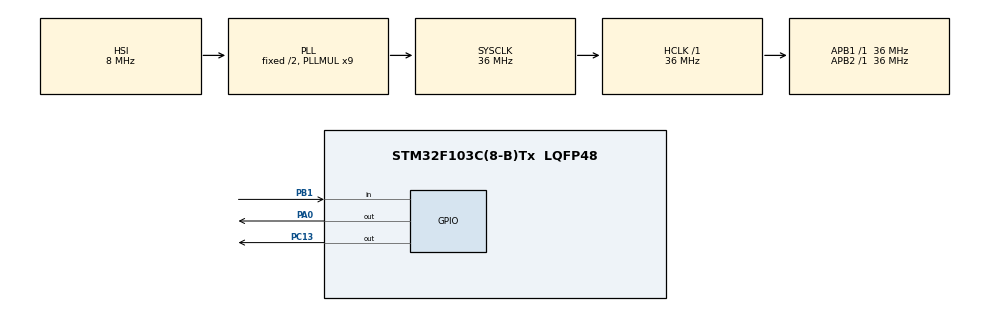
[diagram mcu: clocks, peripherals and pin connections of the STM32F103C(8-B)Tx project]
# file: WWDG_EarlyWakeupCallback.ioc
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Mcu.Family=STM32F1
Mcu.Name=STM32F103C(8-B)Tx
Mcu.Package=LQFP48
NVIC.PriorityGroup=NVIC_PRIORITYGROUP_4
NVIC.WWDG_IRQn=true\:0\:0\:false\:false\:true\:true\:true
PA0-WKUP.Signal=GPIO_Output
PA13.Mode=Serial_Wire
PA13.Signal=SYS_JTMS-SWDIO
PA14.Mode=Serial_Wire
PA14.Signal=SYS_JTCK-SWCLK
PB1.GPIO_PuPd=GPIO_PULLUP
PB1.Signal=GPIO_Input
PC13-TAMPER-RTC.Signal=GPIO_Output
ProjectManager.HeapSize=0x200
ProjectManager.StackSize=0x400
ProjectManager.TargetToolchain=MDK-ARM V5
RCC.AHBFreq_Value=36000000
RCC.APB1Freq_Value=36000000
RCC.APB1TimFreq_Value=36000000
RCC.APB2Freq_Value=36000000
RCC.APB2TimFreq_Value=36000000
RCC.HCLKFreq_Value=36000000
RCC.PLLMUL=RCC_PLL_MUL9
RCC.SYSCLKFreq_VALUE=36000000
RCC.SYSCLKSource=RCC_SYSCLKSOURCE_PLLCLK
RCC.USBFreq_Value=36000000
VP_WWDG_VS_WWDG.Mode=WWDG_Activate
WWDG.Counter=127
WWDG.EWIMode=WWDG_EWI_ENABLE
WWDG.Prescaler=WWDG_PRESCALER_8
WWDG.Window=80
board=custom

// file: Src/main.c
/* USER CODE BEGIN Header */
/**
  ******************************************************************************
  * @file           : main.c
  * @brief          : Main program body
  ******************************************************************************
  * @attention
  *
  * <h2><center>&copy; Copyright (c) 2019 STMicroelectronics.
  * All rights reserved.</center></h2>
  *
  * This software component is licensed by ST under BSD 3-Clause license,
  * the "License"; You may not use this file except in compliance with the
  * License. You may obtain a copy of the License at:
  *                        opensource.org/licenses/BSD-3-Clause
  *
  ******************************************************************************
  */
	/* --COPYRIGHT--,
	 * Copyright (c) 2019, TAPIT Co., Ltd.
	 * https://tapit.vn
	 * ***************************** WWDG_EarlyWakeupCallback *****************************
	 *  Description: The program consists of 2 initial status LEDs that are off. An LED will
			reverse the state to check the operation of the MCU. The remaining LED will be
			turned on when entering the EWC function, off when MCU is reset.
	 *  Version:    1.0
	 *  Author:     Hang Tran
	 *  Release:    May 27, 2019
	 *  Built with CubeMX Version 5.2.0 and Keil C Version 5.26.2
	 **************************************************************************************
 */
/* USER CODE END Header */

#include "main.h"

WWDG_HandleTypeDef hwwdg;

/* USER CODE BEGIN PV */
unsigned char cnt = 0; // Temporary variable for counter value
unsigned char wdt = 0; // Temporary variable for window value

/* USER CODE END PV */

void SystemClock_Config(void);
static void MX_GPIO_Init(void);
static void MX_WWDG_Init(void);
/* USER CODE BEGIN PFP */
void HAL_WWDG_EarlyWakeupCallback(WWDG_HandleTypeDef *hwwdg)
{
	wdt = 0;	// Reset variable for counter value
	cnt = 0;  // Reset variable for window value
	wdt = (WWDG->CFR & 0x7F);      // Read window value
  cnt = (WWDG->CR & 0x7F);       // Read counter value
	if(cnt < wdt)
	{
		WWDG->CR |= 0x7F; 											// Reload the counter to prevent reset MCU
		WWDG->SR = 0x00;												// Clear interrupt flag
		HAL_GPIO_WritePin(GPIOA, GPIO_PIN_0, GPIO_PIN_SET); 			// Watchdog led on
	}
}

/* USER CODE END PFP */

int main(void)
{

  /* MCU Configuration--------------------------------------------------------*/

  /* Reset of all peripherals, Initializes the Flash interface and the Systick. */
  HAL_Init();

  /* Configure the system clock */
  SystemClock_Config();

  /* Initialize all configured peripherals */
  MX_GPIO_Init();
  MX_WWDG_Init();
  /* USER CODE BEGIN 2 */
	HAL_GPIO_WritePin(GPIOA, GPIO_PIN_0, GPIO_PIN_RESET);			// Watchdog LED - off
	HAL_GPIO_WritePin(GPIOC, GPIO_PIN_13, GPIO_PIN_SET); 		// Main LED - off
	HAL_Delay(2000);

  /* USER CODE END 2 */

  /* Infinite loop */
  while (1)
  {

    /* USER CODE BEGIN 3 */
		HAL_GPIO_TogglePin(GPIOC, GPIO_PIN_13); // To show that normal operation is OK
		HAL_Delay(300); // Toggle led every 300ms
		if(HAL_GPIO_ReadPin(GPIOB, GPIO_PIN_1) == RESET) 				// If pressed
		{
			WWDG->CR = 0x80; 																			// Make MCU resets
			while(1);
		}
  }
  /* USER CODE END 3 */
}

void SystemClock_Config(void)
{
  RCC_OscInitTypeDef RCC_OscInitStruct = {0};
  RCC_ClkInitTypeDef RCC_ClkInitStruct = {0};

  /** Initializes the CPU, AHB and APB busses clocks
  */
  RCC_OscInitStruct.OscillatorType = RCC_OSCILLATORTYPE_HSI;
  RCC_OscInitStruct.HSIState = RCC_HSI_ON;
  RCC_OscInitStruct.HSICalibrationValue = RCC_HSICALIBRATION_DEFAULT;
  RCC_OscInitStruct.PLL.PLLState = RCC_PLL_ON;
  RCC_OscInitStruct.PLL.PLLSource = RCC_PLLSOURCE_HSI_DIV2;
  RCC_OscInitStruct.PLL.PLLMUL = RCC_PLL_MUL9;
  if (HAL_RCC_OscConfig(&RCC_OscInitStruct) != HAL_OK)
  {
    Error_Handler();
  }
  /** Initializes the CPU, AHB and APB busses clocks
  */
  RCC_ClkInitStruct.ClockType = RCC_CLOCKTYPE_HCLK|RCC_CLOCKTYPE_SYSCLK
                              |RCC_CLOCKTYPE_PCLK1|RCC_CLOCKTYPE_PCLK2;
  RCC_ClkInitStruct.SYSCLKSource = RCC_SYSCLKSOURCE_PLLCLK;
  RCC_ClkInitStruct.AHBCLKDivider = RCC_SYSCLK_DIV1;
  RCC_ClkInitStruct.APB1CLKDivider = RCC_HCLK_DIV1;
  RCC_ClkInitStruct.APB2CLKDivider = RCC_HCLK_DIV1;

  if (HAL_RCC_ClockConfig(&RCC_ClkInitStruct, FLASH_LATENCY_1) != HAL_OK)
  {
    Error_Handler();
  }
}

static void MX_WWDG_Init(void)
{

  hwwdg.Instance = WWDG;
  hwwdg.Init.Prescaler = WWDG_PRESCALER_8;
  hwwdg.Init.Window = 80;
  hwwdg.Init.Counter = 127;
  hwwdg.Init.EWIMode = WWDG_EWI_ENABLE;
  if (HAL_WWDG_Init(&hwwdg) != HAL_OK)
  {
    Error_Handler();
  }

}

static void MX_GPIO_Init(void)
{
  GPIO_InitTypeDef GPIO_InitStruct = {0};

  /* GPIO Ports Clock Enable */
  __HAL_RCC_GPIOC_CLK_ENABLE();
  __HAL_RCC_GPIOA_CLK_ENABLE();
  __HAL_RCC_GPIOB_CLK_ENABLE();

  /*Configure GPIO pin Output Level */
  HAL_GPIO_WritePin(GPIOC, GPIO_PIN_13, GPIO_PIN_RESET);

  /*Configure GPIO pin Output Level */
  HAL_GPIO_WritePin(GPIOA, GPIO_PIN_0, GPIO_PIN_RESET);

  /*Configure GPIO pin : PC13 */
  GPIO_InitStruct.Pin = GPIO_PIN_13;
  GPIO_InitStruct.Mode = GPIO_MODE_OUTPUT_PP;
  GPIO_InitStruct.Pull = GPIO_NOPULL;
  GPIO_InitStruct.Speed = GPIO_SPEED_FREQ_LOW;
  HAL_GPIO_Init(GPIOC, &GPIO_InitStruct);

  /*Configure GPIO pin : PA0 */
  GPIO_InitStruct.Pin = GPIO_PIN_0;
  GPIO_InitStruct.Mode = GPIO_MODE_OUTPUT_PP;
  GPIO_InitStruct.Pull = GPIO_NOPULL;
  GPIO_InitStruct.Speed = GPIO_SPEED_FREQ_LOW;
  HAL_GPIO_Init(GPIOA, &GPIO_InitStruct);

  /*Configure GPIO pin : PB1 */
  GPIO_InitStruct.Pin = GPIO_PIN_1;
  GPIO_InitStruct.Mode = GPIO_MODE_INPUT;
  GPIO_InitStruct.Pull = GPIO_PULLUP;
  HAL_GPIO_Init(GPIOB, &GPIO_InitStruct);

}

void Error_Handler(void)
{
}

/************************ (C) COPYRIGHT STMicroelectronics *****END OF FILE****/
